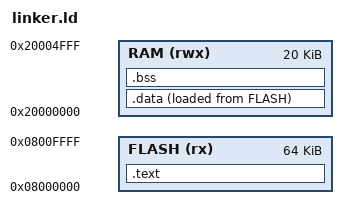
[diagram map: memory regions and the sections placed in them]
ENTRY(v_v_reset_handler)

MEMORY
{
  FLASH (rx) : ORIGIN = 0x08000000, LENGTH = 64K
  RAM (rwx)  : ORIGIN = 0x20000000, LENGTH = 20K
}

_stack_top = ORIGIN(RAM) + LENGTH(RAM);

SECTIONS
{
    .text :
    {
        . = ALIGN(4);
        *(.isr_vector)
        *(.text)
        *(.text.*)
        *(.rodata)
        *(.rodata.*)
        . = ALIGN(4);
        _etext = .;
    } >FLASH

    _data_flash = _etext;

    .data :
    {
        . = ALIGN(4);
        _data_ram = .;
        *(.data)
        *(.data.*)
        . = ALIGN(4);
        _data_end = .;
    } >RAM AT>FLASH

    .bss :
    {
        . = ALIGN(4);
        _bss_start = .;
        *(.bss)
        *(.bss.*)
        *(COMMON)
        . = ALIGN(4);
        _bss_end = .;
    } >RAM
}
